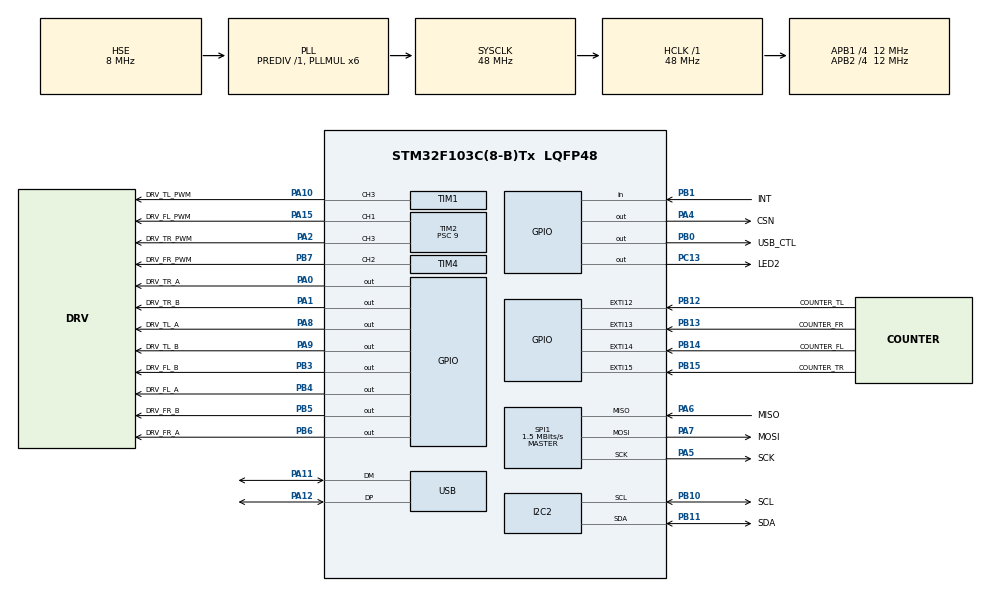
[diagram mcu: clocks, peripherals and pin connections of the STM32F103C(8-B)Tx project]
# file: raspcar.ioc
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Mcu.Family=STM32F1
Mcu.Name=STM32F103C(8-B)Tx
Mcu.Package=LQFP48
NVIC.EXTI15_10_IRQn=true\:0\:0\:false\:false\:true\:true
NVIC.PriorityGroup=NVIC_PRIORITYGROUP_4
NVIC.USB_HP_CAN1_TX_IRQn=true\:0\:0\:false\:false\:true\:true
NVIC.USB_LP_CAN1_RX0_IRQn=true\:0\:0\:false\:false\:true\:false
PA0-WKUP.GPIO_Label=DRV_TR_A
PA0-WKUP.Signal=GPIO_Output
PA1.GPIO_Label=DRV_TR_B
PA1.Signal=GPIO_Output
PA10.GPIO_Label=DRV_TL_PWM
PA10.Signal=S_TIM1_CH3
PA11.Mode=Device
PA11.Signal=USB_DM
PA12.Mode=Device
PA12.Signal=USB_DP
PA13.GPIO_Label=SWDIO
PA13.Mode=Serial_Wire
PA13.Signal=SYS_JTMS-SWDIO
PA14.GPIO_Label=SWCLK
PA14.Mode=Serial_Wire
PA14.Signal=SYS_JTCK-SWCLK
PA15.GPIO_Label=DRV_FL_PWM
PA15.GPIO_Speed=GPIO_SPEED_FREQ_HIGH
PA15.Signal=S_TIM2_CH1_ETR
PA2.GPIO_Label=DRV_TR_PWM
PA2.GPIO_Speed=GPIO_SPEED_FREQ_HIGH
PA2.Signal=S_TIM2_CH3
PA4.GPIO_Label=CSN
PA4.Signal=GPIO_Output
PA5.GPIO_Label=SCK
PA5.Mode=Full_Duplex_Master
PA5.Signal=SPI1_SCK
PA6.GPIO_Label=MISO
PA6.Mode=Full_Duplex_Master
PA6.Signal=SPI1_MISO
PA7.GPIO_Label=MOSI
PA7.Mode=Full_Duplex_Master
PA7.Signal=SPI1_MOSI
PA8.GPIO_Label=DRV_TL_A
PA8.Signal=GPIO_Output
PA9.GPIO_Label=DRV_TL_B
PA9.Signal=GPIO_Output
PB0.GPIO_Label=USB_CTL
PB0.Signal=GPIO_Output
PB1.GPIO_Label=INT
PB1.Signal=GPIO_Input
PB10.GPIO_Label=SCL
PB10.Mode=I2C
PB10.Signal=I2C2_SCL
PB11.GPIO_Label=SDA
PB11.Mode=I2C
PB11.Signal=I2C2_SDA
PB12.GPIO_Label=COUNTER_TL
PB12.Signal=GPXTI12
PB13.GPIO_Label=COUNTER_FR
PB13.Signal=GPXTI13
PB14.GPIO_Label=COUNTER_FL
PB14.Signal=GPXTI14
PB15.GPIO_Label=COUNTER_TR
PB15.Signal=GPXTI15
PB3.GPIO_Label=DRV_FL_B
PB3.Signal=GPIO_Output
PB4.GPIO_Label=DRV_FL_A
PB4.Signal=GPIO_Output
PB5.GPIO_Label=DRV_FR_B
PB5.Signal=GPIO_Output
PB6.GPIO_Label=DRV_FR_A
PB6.Signal=GPIO_Output
PB7.GPIO_Label=DRV_FR_PWM
PB7.GPIO_Speed=GPIO_SPEED_FREQ_HIGH
PB7.Signal=S_TIM4_CH2
PC13-TAMPER-RTC.GPIO_Label=LED2
PC13-TAMPER-RTC.Signal=GPIO_Output
PC14-OSC32_IN.Mode=LSE-External-Oscillator
PC14-OSC32_IN.Signal=RCC_OSC32_IN
PC15-OSC32_OUT.Mode=LSE-External-Oscillator
PC15-OSC32_OUT.Signal=RCC_OSC32_OUT
PD0-OSC_IN.Mode=HSE-External-Oscillator
PD0-OSC_IN.Signal=RCC_OSC_IN
PD1-OSC_OUT.Mode=HSE-External-Oscillator
PD1-OSC_OUT.Signal=RCC_OSC_OUT
ProjectManager.HeapSize=0x200
ProjectManager.StackSize=0x400
ProjectManager.TargetToolchain=MDK-ARM V5
RCC.AHBFreq_Value=48000000
RCC.APB1CLKDivider=RCC_HCLK_DIV4
RCC.APB1Freq_Value=12000000
RCC.APB1TimFreq_Value=24000000
RCC.APB2CLKDivider=RCC_HCLK_DIV4
RCC.APB2Freq_Value=12000000
RCC.APB2TimFreq_Value=24000000
RCC.HCLKFreq_Value=48000000
RCC.PLLMUL=RCC_PLL_MUL6
RCC.SYSCLKFreq_VALUE=48000000
RCC.SYSCLKSource=RCC_SYSCLKSOURCE_PLLCLK
RCC.USBFreq_Value=48000000
SH.S_TIM1_CH3.0=TIM1_CH3,PWM Generation3 CH3
SH.S_TIM2_CH1_ETR.0=TIM2_CH1,PWM Generation1 CH1
SH.S_TIM2_CH3.0=TIM2_CH3,PWM Generation3 CH3
SH.S_TIM4_CH2.0=TIM4_CH2,PWM Generation2 CH2
SPI1.BaudRatePrescaler=SPI_BAUDRATEPRESCALER_8
SPI1.CalculateBaudRate=1.5 MBits/s
SPI1.Direction=SPI_DIRECTION_2LINES
SPI1.Mode=SPI_MODE_MASTER
SPI1.VirtualType=VM_MASTER
TIM1.AutoReloadPreload=TIM_AUTORELOAD_PRELOAD_ENABLE
TIM1.Channel-PWM\ Generation3\ CH3=TIM_CHANNEL_3
TIM1.OCFastMode_PWM-PWM\ Generation3\ CH3=TIM_OCFAST_DISABLE
TIM1.OCIdleState_3=TIM_OCIDLESTATE_RESET
TIM1.OCPolarity_3=TIM_OCPOLARITY_HIGH
TIM1.Period=99
TIM1.Prescaler=9
TIM2.AutoReloadPreload=TIM_AUTORELOAD_PRELOAD_ENABLE
TIM2.Channel-PWM\ Generation1\ CH1=TIM_CHANNEL_1
TIM2.Channel-PWM\ Generation3\ CH3=TIM_CHANNEL_3
TIM2.ClockDivision=TIM_CLOCKDIVISION_DIV1
TIM2.Period=99
TIM2.Prescaler=9
TIM2.Pulse-PWM\ Generation1\ CH1=0
TIM2.Pulse-PWM\ Generation3\ CH3=0
TIM4.AutoReloadPreload=TIM_AUTORELOAD_PRELOAD_ENABLE
TIM4.Channel-PWM\ Generation2\ CH2=TIM_CHANNEL_2
TIM4.Period=99
TIM4.Prescaler=9
USB.ep0_mps=DEP0CTL_MPS_64
USB_DEVICE.CLASS_NAME_FS=CUSTOMHID
USB_DEVICE.PID_CUSTOMHID_FS=0x5750
USB_DEVICE.USBD_CUSTOMHID_OUTREPORT_BUF_SIZE=64
USB_DEVICE.USBD_CUSTOM_HID_REPORT_DESC_SIZE=42
USB_DEVICE.VID=0x483
USB_DEVICE.VirtualMode=CustomHid
USB_DEVICE.VirtualModeFS=Custom_Hid_FS
VP_USB_DEVICE_VS_USB_DEVICE_CUSTOM_HID_FS.Mode=CUSTOM_HID_FS
board=custom

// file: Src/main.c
/**
  ******************************************************************************
  * @file           : main.c
  * @brief          : Main program body
  ******************************************************************************
  * This notice applies to any and all portions of this file
  * that are not between comment pairs USER CODE BEGIN and
  * USER CODE END. Other portions of this file, whether
  * inserted by the user or by software development tools
  * are owned by their respective copyright owners.
  *
  * Copyright (c) 2018 STMicroelectronics International N.V.
  * All rights reserved.
  *
  * Redistribution and use in source and binary forms, with or without
  * modification, are permitted, provided that the following conditions are met:
  *
  * 1. Redistribution of source code must retain the above copyright notice,
  *    this list of conditions and the following disclaimer.
  * 2. Redistributions in binary form must reproduce the above copyright notice,
  *    this list of conditions and the following disclaimer in the documentation
  *    and/or other materials provided with the distribution.
  * 3. Neither the name of STMicroelectronics nor the names of other
  *    contributors to this software may be used to endorse or promote products
  *    derived from this software without specific written permission.
  * 4. This software, including modifications and/or derivative works of this
  *    software, must execute solely and exclusively on microcontroller or
  *    microprocessor devices manufactured by or for STMicroelectronics.
  * 5. Redistribution and use of this software other than as permitted under
  *    this license is void and will automatically terminate your rights under
  *    this license.
  *
  * THIS SOFTWARE IS PROVIDED BY STMICROELECTRONICS AND CONTRIBUTORS "AS IS"
  * AND ANY EXPRESS, IMPLIED OR STATUTORY WARRANTIES, INCLUDING, BUT NOT
  * LIMITED TO, THE IMPLIED WARRANTIES OF MERCHANTABILITY, FITNESS FOR A
  * PARTICULAR PURPOSE AND NON-INFRINGEMENT OF THIRD PARTY INTELLECTUAL PROPERTY
  * RIGHTS ARE DISCLAIMED TO THE FULLEST EXTENT PERMITTED BY LAW. IN NO EVENT
  * SHALL STMICROELECTRONICS OR CONTRIBUTORS BE LIABLE FOR ANY DIRECT, INDIRECT,
  * INCIDENTAL, SPECIAL, EXEMPLARY, OR CONSEQUENTIAL DAMAGES (INCLUDING, BUT NOT
  * LIMITED TO, PROCUREMENT OF SUBSTITUTE GOODS OR SERVICES; LOSS OF USE, DATA,
  * OR PROFITS; OR BUSINESS INTERRUPTION) HOWEVER CAUSED AND ON ANY THEORY OF
  * LIABILITY, WHETHER IN CONTRACT, STRICT LIABILITY, OR TORT (INCLUDING
  * NEGLIGENCE OR OTHERWISE) ARISING IN ANY WAY OUT OF THE USE OF THIS SOFTWARE,
  * EVEN IF ADVISED OF THE POSSIBILITY OF SUCH DAMAGE.
  *
  ******************************************************************************
  */
#include "main.h"
#include "stm32f1xx_hal.h"
#include "usb_device.h"

/* USER CODE BEGIN Includes */
#include "stm32f1xx_hal_tim.h"
#include "stm32f1xx_hal_gpio.h"
#include "usbd_customhid.h"
#include "control.h"
/* USER CODE END Includes */

I2C_HandleTypeDef hi2c2;

SPI_HandleTypeDef hspi1;

TIM_HandleTypeDef htim1;
TIM_HandleTypeDef htim2;
TIM_HandleTypeDef htim4;

/* USER CODE BEGIN PV */
/* Private variables ---------------------------------------------------------*/

/* USER CODE END PV */

void SystemClock_Config(void);
static void MX_GPIO_Init(void);
static void MX_SPI1_Init(void);
static void MX_I2C2_Init(void);
static void MX_TIM2_Init(void);
static void MX_TIM4_Init(void);
static void MX_TIM1_Init(void);

void HAL_TIM_MspPostInit(TIM_HandleTypeDef *htim);

/* USER CODE BEGIN PFP */
/* Private function prototypes -----------------------------------------------*/

/* USER CODE END PFP */

int main(void)
{

  /* MCU Configuration----------------------------------------------------------*/

  /* Reset of all peripherals, Initializes the Flash interface and the Systick. */
  HAL_Init();

  /* Configure the system clock */
  SystemClock_Config();

  /* Initialize all configured peripherals */
  MX_GPIO_Init();
  MX_SPI1_Init();
  MX_USB_DEVICE_Init();
  MX_I2C2_Init();
  MX_TIM2_Init();
  MX_TIM4_Init();
  MX_TIM1_Init();
  /* USER CODE BEGIN 2 */
  MainLoop();
  /* USER CODE END 2 */

  /* Infinite loop */
  while (1)
  {

  }

}

void SystemClock_Config(void)
{

  RCC_OscInitTypeDef RCC_OscInitStruct;
  RCC_ClkInitTypeDef RCC_ClkInitStruct;
  RCC_PeriphCLKInitTypeDef PeriphClkInit;

    /**Initializes the CPU, AHB and APB busses clocks
    */
  RCC_OscInitStruct.OscillatorType = RCC_OSCILLATORTYPE_HSE;
  RCC_OscInitStruct.HSEState = RCC_HSE_ON;
  RCC_OscInitStruct.HSEPredivValue = RCC_HSE_PREDIV_DIV1;
  RCC_OscInitStruct.HSIState = RCC_HSI_ON;
  RCC_OscInitStruct.PLL.PLLState = RCC_PLL_ON;
  RCC_OscInitStruct.PLL.PLLSource = RCC_PLLSOURCE_HSE;
  RCC_OscInitStruct.PLL.PLLMUL = RCC_PLL_MUL6;
  if (HAL_RCC_OscConfig(&RCC_OscInitStruct) != HAL_OK)
  {
    _Error_Handler(__FILE__, __LINE__);
  }

    /**Initializes the CPU, AHB and APB busses clocks
    */
  RCC_ClkInitStruct.ClockType = RCC_CLOCKTYPE_HCLK|RCC_CLOCKTYPE_SYSCLK
                              |RCC_CLOCKTYPE_PCLK1|RCC_CLOCKTYPE_PCLK2;
  RCC_ClkInitStruct.SYSCLKSource = RCC_SYSCLKSOURCE_PLLCLK;
  RCC_ClkInitStruct.AHBCLKDivider = RCC_SYSCLK_DIV1;
  RCC_ClkInitStruct.APB1CLKDivider = RCC_HCLK_DIV4;
  RCC_ClkInitStruct.APB2CLKDivider = RCC_HCLK_DIV4;

  if (HAL_RCC_ClockConfig(&RCC_ClkInitStruct, FLASH_LATENCY_1) != HAL_OK)
  {
    _Error_Handler(__FILE__, __LINE__);
  }

  PeriphClkInit.PeriphClockSelection = RCC_PERIPHCLK_USB;
  PeriphClkInit.UsbClockSelection = RCC_USBCLKSOURCE_PLL;
  if (HAL_RCCEx_PeriphCLKConfig(&PeriphClkInit) != HAL_OK)
  {
    _Error_Handler(__FILE__, __LINE__);
  }

    /**Configure the Systick interrupt time
    */
  HAL_SYSTICK_Config(HAL_RCC_GetHCLKFreq()/1000);

    /**Configure the Systick
    */
  HAL_SYSTICK_CLKSourceConfig(SYSTICK_CLKSOURCE_HCLK);

  /* SysTick_IRQn interrupt configuration */
  HAL_NVIC_SetPriority(SysTick_IRQn, 0, 0);
}

/* I2C2 init function */
static void MX_I2C2_Init(void)
{

  hi2c2.Instance = I2C2;
  hi2c2.Init.ClockSpeed = 100000;
  hi2c2.Init.DutyCycle = I2C_DUTYCYCLE_2;
  hi2c2.Init.OwnAddress1 = 0;
  hi2c2.Init.AddressingMode = I2C_ADDRESSINGMODE_7BIT;
  hi2c2.Init.DualAddressMode = I2C_DUALADDRESS_DISABLE;
  hi2c2.Init.OwnAddress2 = 0;
  hi2c2.Init.GeneralCallMode = I2C_GENERALCALL_DISABLE;
  hi2c2.Init.NoStretchMode = I2C_NOSTRETCH_DISABLE;
  if (HAL_I2C_Init(&hi2c2) != HAL_OK)
  {
    _Error_Handler(__FILE__, __LINE__);
  }

}

/* SPI1 init function */
static void MX_SPI1_Init(void)
{

  /* SPI1 parameter configuration*/
  hspi1.Instance = SPI1;
  hspi1.Init.Mode = SPI_MODE_MASTER;
  hspi1.Init.Direction = SPI_DIRECTION_2LINES;
  hspi1.Init.DataSize = SPI_DATASIZE_8BIT;
  hspi1.Init.CLKPolarity = SPI_POLARITY_LOW;
  hspi1.Init.CLKPhase = SPI_PHASE_1EDGE;
  hspi1.Init.NSS = SPI_NSS_SOFT;
  hspi1.Init.BaudRatePrescaler = SPI_BAUDRATEPRESCALER_8;
  hspi1.Init.FirstBit = SPI_FIRSTBIT_MSB;
  hspi1.Init.TIMode = SPI_TIMODE_DISABLE;
  hspi1.Init.CRCCalculation = SPI_CRCCALCULATION_DISABLE;
  hspi1.Init.CRCPolynomial = 10;
  if (HAL_SPI_Init(&hspi1) != HAL_OK)
  {
    _Error_Handler(__FILE__, __LINE__);
  }

}

/* TIM1 init function */
static void MX_TIM1_Init(void)
{

  TIM_MasterConfigTypeDef sMasterConfig;
  TIM_OC_InitTypeDef sConfigOC;
  TIM_BreakDeadTimeConfigTypeDef sBreakDeadTimeConfig;

  htim1.Instance = TIM1;
  htim1.Init.Prescaler = 9;
  htim1.Init.CounterMode = TIM_COUNTERMODE_UP;
  htim1.Init.Period = 99;
  htim1.Init.ClockDivision = TIM_CLOCKDIVISION_DIV1;
  htim1.Init.RepetitionCounter = 0;
  htim1.Init.AutoReloadPreload = TIM_AUTORELOAD_PRELOAD_ENABLE;
  if (HAL_TIM_PWM_Init(&htim1) != HAL_OK)
  {
    _Error_Handler(__FILE__, __LINE__);
  }

  sMasterConfig.MasterOutputTrigger = TIM_TRGO_RESET;
  sMasterConfig.MasterSlaveMode = TIM_MASTERSLAVEMODE_DISABLE;
  if (HAL_TIMEx_MasterConfigSynchronization(&htim1, &sMasterConfig) != HAL_OK)
  {
    _Error_Handler(__FILE__, __LINE__);
  }

  sConfigOC.OCMode = TIM_OCMODE_PWM1;
  sConfigOC.Pulse = 0;
  sConfigOC.OCPolarity = TIM_OCPOLARITY_HIGH;
  sConfigOC.OCNPolarity = TIM_OCNPOLARITY_HIGH;
  sConfigOC.OCFastMode = TIM_OCFAST_DISABLE;
  sConfigOC.OCIdleState = TIM_OCIDLESTATE_RESET;
  sConfigOC.OCNIdleState = TIM_OCNIDLESTATE_RESET;
  if (HAL_TIM_PWM_ConfigChannel(&htim1, &sConfigOC, TIM_CHANNEL_3) != HAL_OK)
  {
    _Error_Handler(__FILE__, __LINE__);
  }

  sBreakDeadTimeConfig.OffStateRunMode = TIM_OSSR_DISABLE;
  sBreakDeadTimeConfig.OffStateIDLEMode = TIM_OSSI_DISABLE;
  sBreakDeadTimeConfig.LockLevel = TIM_LOCKLEVEL_OFF;
  sBreakDeadTimeConfig.DeadTime = 0;
  sBreakDeadTimeConfig.BreakState = TIM_BREAK_DISABLE;
  sBreakDeadTimeConfig.BreakPolarity = TIM_BREAKPOLARITY_HIGH;
  sBreakDeadTimeConfig.AutomaticOutput = TIM_AUTOMATICOUTPUT_DISABLE;
  if (HAL_TIMEx_ConfigBreakDeadTime(&htim1, &sBreakDeadTimeConfig) != HAL_OK)
  {
    _Error_Handler(__FILE__, __LINE__);
  }

  HAL_TIM_MspPostInit(&htim1);

}

/* TIM2 init function */
static void MX_TIM2_Init(void)
{

  TIM_MasterConfigTypeDef sMasterConfig;
  TIM_OC_InitTypeDef sConfigOC;

  htim2.Instance = TIM2;
  htim2.Init.Prescaler = 9;
  htim2.Init.CounterMode = TIM_COUNTERMODE_UP;
  htim2.Init.Period = 99;
  htim2.Init.ClockDivision = TIM_CLOCKDIVISION_DIV1;
  htim2.Init.AutoReloadPreload = TIM_AUTORELOAD_PRELOAD_ENABLE;
  if (HAL_TIM_PWM_Init(&htim2) != HAL_OK)
  {
    _Error_Handler(__FILE__, __LINE__);
  }

  sMasterConfig.MasterOutputTrigger = TIM_TRGO_RESET;
  sMasterConfig.MasterSlaveMode = TIM_MASTERSLAVEMODE_DISABLE;
  if (HAL_TIMEx_MasterConfigSynchronization(&htim2, &sMasterConfig) != HAL_OK)
  {
    _Error_Handler(__FILE__, __LINE__);
  }

  sConfigOC.OCMode = TIM_OCMODE_PWM1;
  sConfigOC.Pulse = 0;
  sConfigOC.OCPolarity = TIM_OCPOLARITY_HIGH;
  sConfigOC.OCFastMode = TIM_OCFAST_DISABLE;
  if (HAL_TIM_PWM_ConfigChannel(&htim2, &sConfigOC, TIM_CHANNEL_1) != HAL_OK)
  {
    _Error_Handler(__FILE__, __LINE__);
  }

  if (HAL_TIM_PWM_ConfigChannel(&htim2, &sConfigOC, TIM_CHANNEL_3) != HAL_OK)
  {
    _Error_Handler(__FILE__, __LINE__);
  }

  HAL_TIM_MspPostInit(&htim2);

}

/* TIM4 init function */
static void MX_TIM4_Init(void)
{

  TIM_MasterConfigTypeDef sMasterConfig;
  TIM_OC_InitTypeDef sConfigOC;

  htim4.Instance = TIM4;
  htim4.Init.Prescaler = 9;
  htim4.Init.CounterMode = TIM_COUNTERMODE_UP;
  htim4.Init.Period = 99;
  htim4.Init.ClockDivision = TIM_CLOCKDIVISION_DIV1;
  htim4.Init.AutoReloadPreload = TIM_AUTORELOAD_PRELOAD_ENABLE;
  if (HAL_TIM_PWM_Init(&htim4) != HAL_OK)
  {
    _Error_Handler(__FILE__, __LINE__);
  }

  sMasterConfig.MasterOutputTrigger = TIM_TRGO_RESET;
  sMasterConfig.MasterSlaveMode = TIM_MASTERSLAVEMODE_DISABLE;
  if (HAL_TIMEx_MasterConfigSynchronization(&htim4, &sMasterConfig) != HAL_OK)
  {
    _Error_Handler(__FILE__, __LINE__);
  }

  sConfigOC.OCMode = TIM_OCMODE_PWM1;
  sConfigOC.Pulse = 0;
  sConfigOC.OCPolarity = TIM_OCPOLARITY_HIGH;
  sConfigOC.OCFastMode = TIM_OCFAST_DISABLE;
  if (HAL_TIM_PWM_ConfigChannel(&htim4, &sConfigOC, TIM_CHANNEL_2) != HAL_OK)
  {
    _Error_Handler(__FILE__, __LINE__);
  }

  HAL_TIM_MspPostInit(&htim4);

}

/** Configure pins as
        * Analog
        * Input
        * Output
        * EVENT_OUT
        * EXTI
*/
static void MX_GPIO_Init(void)
{

  GPIO_InitTypeDef GPIO_InitStruct;

  /* GPIO Ports Clock Enable */
  __HAL_RCC_GPIOC_CLK_ENABLE();
  __HAL_RCC_GPIOD_CLK_ENABLE();
  __HAL_RCC_GPIOA_CLK_ENABLE();
  __HAL_RCC_GPIOB_CLK_ENABLE();

  /*Configure GPIO pin Output Level */
  HAL_GPIO_WritePin(LED2_GPIO_Port, LED2_Pin, GPIO_PIN_RESET);

  /*Configure GPIO pin Output Level */
  HAL_GPIO_WritePin(GPIOA, DRV_TR_A_Pin|DRV_TR_B_Pin|CSN_Pin|DRV_TL_A_Pin
                          |DRV_TL_B_Pin, GPIO_PIN_RESET);

  /*Configure GPIO pin Output Level */
  HAL_GPIO_WritePin(GPIOB, USB_CTL_Pin|DRV_FL_B_Pin|DRV_FL_A_Pin|DRV_FR_B_Pin
                          |DRV_FR_A_Pin, GPIO_PIN_RESET);

  /*Configure GPIO pin : LED2_Pin */
  GPIO_InitStruct.Pin = LED2_Pin;
  GPIO_InitStruct.Mode = GPIO_MODE_OUTPUT_PP;
  GPIO_InitStruct.Pull = GPIO_NOPULL;
  GPIO_InitStruct.Speed = GPIO_SPEED_FREQ_LOW;
  HAL_GPIO_Init(LED2_GPIO_Port, &GPIO_InitStruct);

  /*Configure GPIO pins : DRV_TR_A_Pin DRV_TR_B_Pin CSN_Pin DRV_TL_A_Pin
                           DRV_TL_B_Pin */
  GPIO_InitStruct.Pin = DRV_TR_A_Pin|DRV_TR_B_Pin|CSN_Pin|DRV_TL_A_Pin
                          |DRV_TL_B_Pin;
  GPIO_InitStruct.Mode = GPIO_MODE_OUTPUT_PP;
  GPIO_InitStruct.Pull = GPIO_NOPULL;
  GPIO_InitStruct.Speed = GPIO_SPEED_FREQ_LOW;
  HAL_GPIO_Init(GPIOA, &GPIO_InitStruct);

  /*Configure GPIO pins : USB_CTL_Pin DRV_FL_B_Pin DRV_FL_A_Pin DRV_FR_B_Pin
                           DRV_FR_A_Pin */
  GPIO_InitStruct.Pin = USB_CTL_Pin|DRV_FL_B_Pin|DRV_FL_A_Pin|DRV_FR_B_Pin
                          |DRV_FR_A_Pin;
  GPIO_InitStruct.Mode = GPIO_MODE_OUTPUT_PP;
  GPIO_InitStruct.Pull = GPIO_NOPULL;
  GPIO_InitStruct.Speed = GPIO_SPEED_FREQ_LOW;
  HAL_GPIO_Init(GPIOB, &GPIO_InitStruct);

  /*Configure GPIO pin : INT_Pin */
  GPIO_InitStruct.Pin = INT_Pin;
  GPIO_InitStruct.Mode = GPIO_MODE_INPUT;
  GPIO_InitStruct.Pull = GPIO_NOPULL;
  HAL_GPIO_Init(INT_GPIO_Port, &GPIO_InitStruct);

  /*Configure GPIO pins : COUNTER_TL_Pin COUNTER_FR_Pin COUNTER_FL_Pin COUNTER_TR_Pin */
  GPIO_InitStruct.Pin = COUNTER_TL_Pin|COUNTER_FR_Pin|COUNTER_FL_Pin|COUNTER_TR_Pin;
  GPIO_InitStruct.Mode = GPIO_MODE_IT_RISING;
  GPIO_InitStruct.Pull = GPIO_NOPULL;
  HAL_GPIO_Init(GPIOB, &GPIO_InitStruct);

  /* EXTI interrupt init*/
  HAL_NVIC_SetPriority(EXTI15_10_IRQn, 0, 0);
  HAL_NVIC_EnableIRQ(EXTI15_10_IRQn);

}

void _Error_Handler(char *file, int line)
{
  while (1)
  {
  }
}

/************************ (C) COPYRIGHT STMicroelectronics *****END OF FILE****/
